# PMM_367.0 register map
Vendor: Texas Instruments
Peripheral module from a debugger description file (folder msp430).
Registers are 16-bit, read-write, no defined reset value unless marked. A register's access mark holds for its fields unless they carry their own. Offsets are as the file gives them; lines under a group give offsets from that group; [hi:lo] are bit positions; {n}, {i} and the like mark numbered series; 'fields as' and 'values as' point back to an identical list; <NAME> marks a mode.

## PMM
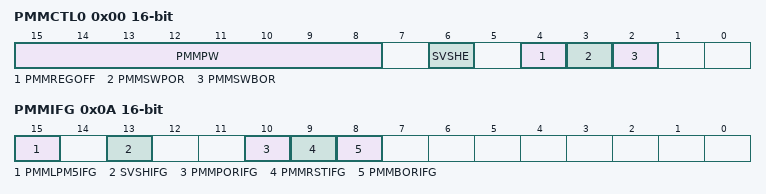
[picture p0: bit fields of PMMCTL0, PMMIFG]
0x00 PMMCTL0 — PMM control register 0
  [15:8] PMMPW — PMM password.
  [6] SVSHE — High-side SVS enable.
    0=High-side SVS (SVSH) is disabled in LPM2, LPM3, LPM4, LPM3.5, and LPM4.5. SVSH is always enabled in active mode, LPM0, and LPM1.; 1=SVSH is always enabled
  [4] PMMREGOFF — Regulator off
    0=Regulator remains on when going into LPM3 or LPM4; 1=Regulator is turned off when going to LPM3 or LPM4. System enters LPM3.5 or LPM4.5, respectively.
  [3] PMMSWPOR — Software POR.
    0=Normal operation; 1=Set to 1 to trigger a POR
  [2] PMMSWBOR — Software brownout reset.
    0=Normal operation; 1=Set to 1 to trigger a BOR
0x0A PMMIFG — PMM interrupt flag register
  [15] PMMLPM5IFG — LPMx.5 flag.
    0=Reset not due to wake-up from LPMx.5; 1=Reset due to wake-up from LPMx.5
  [13] SVSHIFG — High-side SVS interrupt flag.
    0=Reset not due to SVSH; 1=Reset due to SVSH
  [10] PMMPORIFG — PMM software POR interrupt flag.
    0=PMMBORIFG_0 (Reset not due to PMMSWPOR); 1=PMMBORIFG_1 (Reset due to PMMSWPOR)
  [9] PMMRSTIFG — PMM reset pin interrupt flag.
    0=PMMBORIFG_0 (Reset not due to reset pin); 1=PMMBORIFG_1 (Reset due to reset pin)
  [8] PMMBORIFG — PMM software brownout reset interrupt flag.
    0=Reset not due to PMMSWBOR; 1=Reset due to PMMSWBOR
0x10 PM5CTL0 — Power mode 5 control register 0
  [0] LOCKLPM5 — LPMx.5 Lock Bit
    0=LPMx.5 configuration is not locked and defaults to its reset condition; 1=LPMx.5 configuration remains locked. Pin state is held during LPMx.5 entry and exit.
